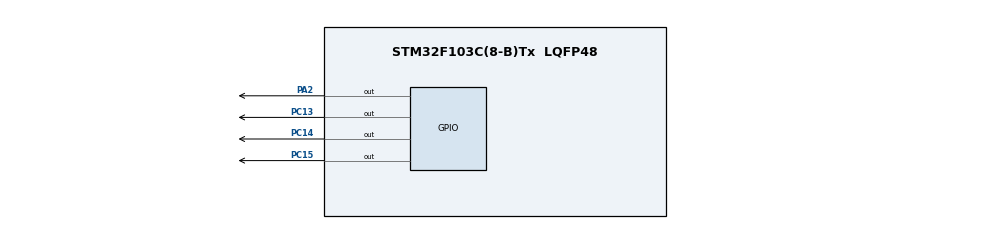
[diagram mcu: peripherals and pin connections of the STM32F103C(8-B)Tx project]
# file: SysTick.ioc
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Mcu.Family=STM32F1
Mcu.Name=STM32F103C(8-B)Tx
Mcu.Package=LQFP48
NVIC.PriorityGroup=NVIC_PRIORITYGROUP_4
PA13.Mode=Serial_Wire
PA13.Signal=SYS_JTMS-SWDIO
PA14.Mode=Serial_Wire
PA14.Signal=SYS_JTCK-SWCLK
PA2.Signal=GPIO_Output
PC13-TAMPER-RTC.Signal=GPIO_Output
PC14-OSC32_IN.Signal=GPIO_Output
PC15-OSC32_OUT.Signal=GPIO_Output
PD0-OSC_IN.Mode=HSE-External-Oscillator
PD0-OSC_IN.Signal=RCC_OSC_IN
PD1-OSC_OUT.Mode=HSE-External-Oscillator
PD1-OSC_OUT.Signal=RCC_OSC_OUT
ProjectManager.HeapSize=0x200
ProjectManager.StackSize=0x400
ProjectManager.TargetToolchain=STM32CubeIDE
RCC.APB1CLKDivider=RCC_HCLK_DIV4
RCC.APB1Freq_Value=2000000
RCC.APB1TimFreq_Value=4000000
RCC.APB2CLKDivider=RCC_HCLK_DIV4
RCC.APB2Freq_Value=2000000
RCC.APB2TimFreq_Value=4000000
RCC.SYSCLKSource=RCC_SYSCLKSOURCE_HSE
board=custom

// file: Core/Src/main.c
/* USER CODE BEGIN Header */
/**
  ******************************************************************************
  * @file           : main.c
  * @brief          : Main program body
  ******************************************************************************
  * @attention
  *
  * <h2><center>&copy; Copyright (c) 2023 STMicroelectronics.
  * All rights reserved.</center></h2>
  *
  * This software component is licensed by ST under BSD 3-Clause license,
  * the "License"; You may not use this file except in compliance with the
  * License. You may obtain a copy of the License at:
  *                        opensource.org/licenses/BSD-3-Clause
  *
  ******************************************************************************
  */
/* USER CODE END Header */
#include "main.h"

/* USER CODE BEGIN PTD */
typedef struct
{
	uint8_t Periodicety;
	void (*Fptr) (void);
}Task;
/* USER CODE END PTD */

/* USER CODE BEGIN PM */
#define NO_OF_TASKS	3

#define FIRST_PRIORITY	0
#define SECOND_PRIORITY	1
#define THIRD_PRIORITY	2

#define PERIODICITY_1ms		1
#define PERIODICITY_2ms		2
#define PERIODICITY_5ms		5

/* USER CODE END PM */

unsigned char Tick_Counts;
Task arr[NO_OF_TASKS];

void SystemClock_Config(void);
static void MX_GPIO_Init(void);

void RED_Toggle(void);
void Yellow_Toggle(void);
void Blue_Toggle(void);
void Green_Toggle(void);

void TASKS_CREATION(uint8_t priority,uint8_t Periodicety, void (*Fptr) (void))
{
	arr[priority].Periodicety=Periodicety;
	arr[priority].Fptr=Fptr;
}

void SCHEDULER(void)
{
	uint8_t i;
	for(i=0; i < NO_OF_TASKS; i++)
	{
		if(Tick_Counts % arr[i].Periodicety == 0)
		{
			arr[i].Fptr();
		}
		else
		{
			/*	do nothing	*/
		}
	}
}

int main(void)
{

  /* MCU Configuration--------------------------------------------------------*/

  /* Reset of all peripherals, Initializes the Flash interface and the Systick. */
  HAL_Init();

  /* Configure the system clock */
  SystemClock_Config();

  /* Initialize all configured peripherals */
  MX_GPIO_Init();
  HAL_SYSTICK_CLKSourceConfig(SYSTICK_CLKSOURCE_HCLK_DIV8);
  HAL_SYSTICK_Config(10000000);

  /*	Create RTOS Tasks		*/

  TASKS_CREATION(FIRST_PRIORITY,PERIODICITY_1ms,RED_Toggle);
  TASKS_CREATION(SECOND_PRIORITY,PERIODICITY_2ms,Green_Toggle);
  TASKS_CREATION(THIRD_PRIORITY,PERIODICITY_5ms,Blue_Toggle);

  /* Infinite loop */
  while (1)
  {

  }
}
void SysTick_Handler(void)
{
	Tick_Counts++;
	SCHEDULER();
}

void SystemClock_Config(void)
{
  RCC_OscInitTypeDef RCC_OscInitStruct = {0};
  RCC_ClkInitTypeDef RCC_ClkInitStruct = {0};

  /** Initializes the RCC Oscillators according to the specified parameters
  * in the RCC_OscInitTypeDef structure.
  */
  RCC_OscInitStruct.OscillatorType = RCC_OSCILLATORTYPE_HSE;
  RCC_OscInitStruct.HSEState = RCC_HSE_ON;
  RCC_OscInitStruct.PLL.PLLState = RCC_PLL_NONE;
  if (HAL_RCC_OscConfig(&RCC_OscInitStruct) != HAL_OK)
  {
    Error_Handler();
  }
  /** Initializes the CPU, AHB and APB buses clocks
  */
  RCC_ClkInitStruct.ClockType = RCC_CLOCKTYPE_HCLK|RCC_CLOCKTYPE_SYSCLK
                              |RCC_CLOCKTYPE_PCLK1|RCC_CLOCKTYPE_PCLK2;
  RCC_ClkInitStruct.SYSCLKSource = RCC_SYSCLKSOURCE_HSE;
  RCC_ClkInitStruct.AHBCLKDivider = RCC_SYSCLK_DIV1;
  RCC_ClkInitStruct.APB1CLKDivider = RCC_HCLK_DIV4;
  RCC_ClkInitStruct.APB2CLKDivider = RCC_HCLK_DIV4;

  if (HAL_RCC_ClockConfig(&RCC_ClkInitStruct, FLASH_LATENCY_0) != HAL_OK)
  {
    Error_Handler();
  }
}

static void MX_GPIO_Init(void)
{
  GPIO_InitTypeDef GPIO_InitStruct = {0};

  /* GPIO Ports Clock Enable */
  __HAL_RCC_GPIOC_CLK_ENABLE();
  __HAL_RCC_GPIOD_CLK_ENABLE();
  __HAL_RCC_GPIOA_CLK_ENABLE();

  /*Configure GPIO pin Output Level */
  HAL_GPIO_WritePin(GPIOC, GPIO_PIN_13|GPIO_PIN_14|GPIO_PIN_15, GPIO_PIN_RESET);

  /*Configure GPIO pin Output Level */
  HAL_GPIO_WritePin(GPIOA, GPIO_PIN_2, GPIO_PIN_RESET);

  /*Configure GPIO pins : PC13 PC14 PC15 */
  GPIO_InitStruct.Pin = GPIO_PIN_13|GPIO_PIN_14|GPIO_PIN_15;
  GPIO_InitStruct.Mode = GPIO_MODE_OUTPUT_PP;
  GPIO_InitStruct.Pull = GPIO_NOPULL;
  GPIO_InitStruct.Speed = GPIO_SPEED_FREQ_LOW;
  HAL_GPIO_Init(GPIOC, &GPIO_InitStruct);

  /*Configure GPIO pin : PA2 */
  GPIO_InitStruct.Pin = GPIO_PIN_2;
  GPIO_InitStruct.Mode = GPIO_MODE_OUTPUT_PP;
  GPIO_InitStruct.Pull = GPIO_NOPULL;
  GPIO_InitStruct.Speed = GPIO_SPEED_FREQ_LOW;
  HAL_GPIO_Init(GPIOA, &GPIO_InitStruct);

}

void Error_Handler(void)
{
}

void RED_Toggle(void)
{
	HAL_GPIO_TogglePin(GPIOA,GPIO_PIN_2);
}
void Yellow_Toggle(void)
{
	HAL_GPIO_TogglePin(GPIOC,GPIO_PIN_13);
}
void Blue_Toggle(void)
{
	HAL_GPIO_TogglePin(GPIOC,GPIO_PIN_14);
}
void Green_Toggle(void)
{
	HAL_GPIO_TogglePin(GPIOC,GPIO_PIN_15);
}

/************************ (C) COPYRIGHT STMicroelectronics *****END OF FILE****/
